# moonlight_application register map
Vendor: Nordic Semiconductor; Series: lumos; File version: 1
CPU: CM33 r0p4, little endian, MPU, FPU, 3 interrupt priority bits, 176 interrupts, 4 SAU regions
Registers are 32-bit, read-write, reset 0x0 unless marked. A register's access mark holds for its fields unless they carry their own. Offsets are from the block's base; [hi:lo] are bit positions; lines under a group give offsets from that group; {n}, {i} and the like mark numbered series; 'fields as' and 'values as' point back to an identical list.

## GLOBAL_RADIO_NS (part 2 of 4) — 2.4 GHz radio 0
Base 0x4008A000
Same registers: GLOBAL_RADIO_S 0x5008A000
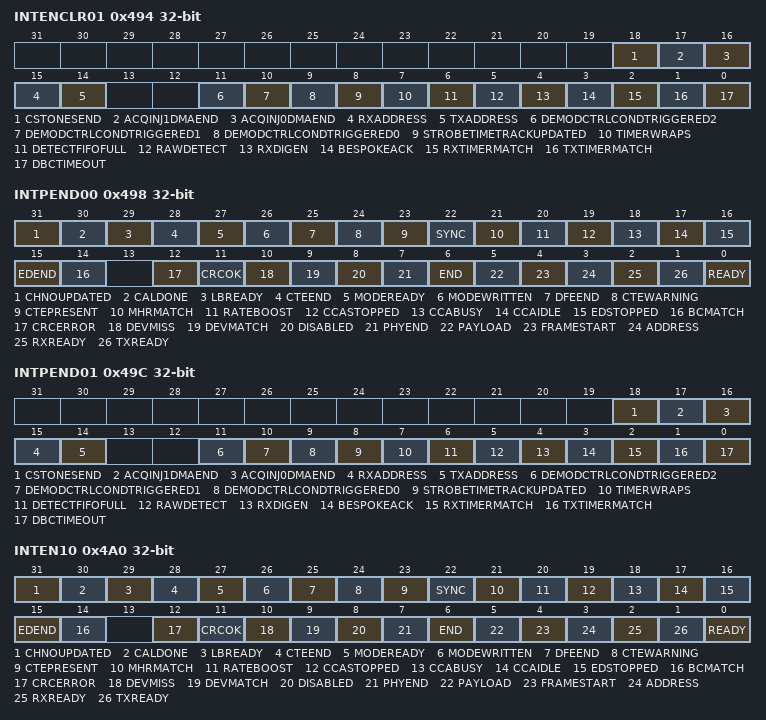
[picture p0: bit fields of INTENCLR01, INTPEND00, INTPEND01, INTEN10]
0x494 INTENCLR01 — Disable interrupt
  [all] fields
    on read: 0=Disabled (Read: Disabled); 1=Enabled (Read: Enabled) | on write: 1=Clear (Disable)
  [18] CSTONESEND — Write '1' to disable interrupt for event CSTONESEND
  [17] ACQINJ1DMAEND — Write '1' to disable interrupt for event ACQINJ1DMAEND
  [16] ACQINJ0DMAEND — Write '1' to disable interrupt for event ACQINJ0DMAEND
  [15] RXADDRESS — Write '1' to disable interrupt for event RXADDRESS
  [14] TXADDRESS — Write '1' to disable interrupt for event TXADDRESS
  [11] DEMODCTRLCONDTRIGGERED2 — Write '1' to disable interrupt for event DEMODCTRLCONDTRIGGERED2
  [10] DEMODCTRLCONDTRIGGERED1 — Write '1' to disable interrupt for event DEMODCTRLCONDTRIGGERED1
  [9] DEMODCTRLCONDTRIGGERED0 — Write '1' to disable interrupt for event DEMODCTRLCONDTRIGGERED0
  [8] STROBETIMETRACKUPDATED — Write '1' to disable interrupt for event STROBETIMETRACKUPDATED
  [7] TIMERWRAPS — Write '1' to disable interrupt for event TIMERWRAPS
  [6] DETECTFIFOFULL — Write '1' to disable interrupt for event DETECTFIFOFULL
  [5] RAWDETECT — Write '1' to disable interrupt for event RAWDETECT
  [4] RXDIGEN — Write '1' to disable interrupt for event RXDIGEN
  [3] BESPOKEACK — Write '1' to disable interrupt for event BESPOKEACK
  [2] RXTIMERMATCH — Write '1' to disable interrupt for event RXTIMERMATCH
  [1] TXTIMERMATCH — Write '1' to disable interrupt for event TXTIMERMATCH
  [0] DBCTIMEOUT — Write '1' to disable interrupt for event DBCTIMEOUT
0x498 INTPEND00 ro — Pending interrupts
  [all] fields
    on read: 0=NotPending (Read: Not pending); 1=Pending (Read: Pending)
  [31] CHNOUPDATED — Read pending status of interrupt for event CHNOUPDATED
  [30] CALDONE — Read pending status of interrupt for event CALDONE
  [29] LBREADY — Read pending status of interrupt for event LBREADY
  [28] CTEEND — Read pending status of interrupt for event CTEEND
  [27] MODEREADY — Read pending status of interrupt for event MODEREADY
  [26] MODEWRITTEN — Read pending status of interrupt for event MODEWRITTEN
  [25] DFEEND — Read pending status of interrupt for event DFEEND
  [24] CTEWARNING — Read pending status of interrupt for event CTEWARNING
  [23] CTEPRESENT — Read pending status of interrupt for event CTEPRESENT
  [22] SYNC — Read pending status of interrupt for event SYNC
  [21] MHRMATCH — Read pending status of interrupt for event MHRMATCH
  [20] RATEBOOST — Read pending status of interrupt for event RATEBOOST
  [19] CCASTOPPED — Read pending status of interrupt for event CCASTOPPED
  [18] CCABUSY — Read pending status of interrupt for event CCABUSY
  [17] CCAIDLE — Read pending status of interrupt for event CCAIDLE
  [16] EDSTOPPED — Read pending status of interrupt for event EDSTOPPED
  [15] EDEND — Read pending status of interrupt for event EDEND
  [14] BCMATCH — Read pending status of interrupt for event BCMATCH
  [12] CRCERROR — Read pending status of interrupt for event CRCERROR
  [11] CRCOK — Read pending status of interrupt for event CRCOK
  [10] DEVMISS — Read pending status of interrupt for event DEVMISS
  [9] DEVMATCH — Read pending status of interrupt for event DEVMATCH
  [8] DISABLED — Read pending status of interrupt for event DISABLED
  [7] PHYEND — Read pending status of interrupt for event PHYEND
  [6] END — Read pending status of interrupt for event END
  [5] PAYLOAD — Read pending status of interrupt for event PAYLOAD
  [4] FRAMESTART — Read pending status of interrupt for event FRAMESTART
  [3] ADDRESS — Read pending status of interrupt for event ADDRESS
  [2] RXREADY — Read pending status of interrupt for event RXREADY
  [1] TXREADY — Read pending status of interrupt for event TXREADY
  [0] READY — Read pending status of interrupt for event READY
0x49C INTPEND01 ro — Pending interrupts
  [all] fields
    values as the fields of INTPEND00
  [18] CSTONESEND — Read pending status of interrupt for event CSTONESEND
  [17] ACQINJ1DMAEND — Read pending status of interrupt for event ACQINJ1DMAEND
  [16] ACQINJ0DMAEND — Read pending status of interrupt for event ACQINJ0DMAEND
  [15] RXADDRESS — Read pending status of interrupt for event RXADDRESS
  [14] TXADDRESS — Read pending status of interrupt for event TXADDRESS
  [11] DEMODCTRLCONDTRIGGERED2 — Read pending status of interrupt for event DEMODCTRLCONDTRIGGERED2
  [10] DEMODCTRLCONDTRIGGERED1 — Read pending status of interrupt for event DEMODCTRLCONDTRIGGERED1
  [9] DEMODCTRLCONDTRIGGERED0 — Read pending status of interrupt for event DEMODCTRLCONDTRIGGERED0
  [8] STROBETIMETRACKUPDATED — Read pending status of interrupt for event STROBETIMETRACKUPDATED
  [7] TIMERWRAPS — Read pending status of interrupt for event TIMERWRAPS
  [6] DETECTFIFOFULL — Read pending status of interrupt for event DETECTFIFOFULL
  [5] RAWDETECT — Read pending status of interrupt for event RAWDETECT
  [4] RXDIGEN — Read pending status of interrupt for event RXDIGEN
  [3] BESPOKEACK — Read pending status of interrupt for event BESPOKEACK
  [2] RXTIMERMATCH — Read pending status of interrupt for event RXTIMERMATCH
  [1] TXTIMERMATCH — Read pending status of interrupt for event TXTIMERMATCH
  [0] DBCTIMEOUT — Read pending status of interrupt for event DBCTIMEOUT
0x4A0 INTEN10 — Enable or disable interrupt
  [all] fields
    0=Disabled; 1=Enabled
  [31] CHNOUPDATED — Enable or disable interrupt for event CHNOUPDATED
  [30] CALDONE — Enable or disable interrupt for event CALDONE
  [29] LBREADY — Enable or disable interrupt for event LBREADY
  [28] CTEEND — Enable or disable interrupt for event CTEEND
  [27] MODEREADY — Enable or disable interrupt for event MODEREADY
  [26] MODEWRITTEN — Enable or disable interrupt for event MODEWRITTEN
  [25] DFEEND — Enable or disable interrupt for event DFEEND
  [24] CTEWARNING — Enable or disable interrupt for event CTEWARNING
  [23] CTEPRESENT — Enable or disable interrupt for event CTEPRESENT
  [22] SYNC — Enable or disable interrupt for event SYNC
  [21] MHRMATCH — Enable or disable interrupt for event MHRMATCH
  [20] RATEBOOST — Enable or disable interrupt for event RATEBOOST
  [19] CCASTOPPED — Enable or disable interrupt for event CCASTOPPED
  [18] CCABUSY — Enable or disable interrupt for event CCABUSY
  [17] CCAIDLE — Enable or disable interrupt for event CCAIDLE
  [16] EDSTOPPED — Enable or disable interrupt for event EDSTOPPED
  [15] EDEND — Enable or disable interrupt for event EDEND
  [14] BCMATCH — Enable or disable interrupt for event BCMATCH
  [12] CRCERROR — Enable or disable interrupt for event CRCERROR
  [11] CRCOK — Enable or disable interrupt for event CRCOK
  [10] DEVMISS — Enable or disable interrupt for event DEVMISS
  [9] DEVMATCH — Enable or disable interrupt for event DEVMATCH
  [8] DISABLED — Enable or disable interrupt for event DISABLED
  [7] PHYEND — Enable or disable interrupt for event PHYEND
  [6] END — Enable or disable interrupt for event END
  [5] PAYLOAD — Enable or disable interrupt for event PAYLOAD
  [4] FRAMESTART — Enable or disable interrupt for event FRAMESTART
  [3] ADDRESS — Enable or disable interrupt for event ADDRESS
  [2] RXREADY — Enable or disable interrupt for event RXREADY
  [1] TXREADY — Enable or disable interrupt for event TXREADY
  [0] READY — Enable or disable interrupt for event READY
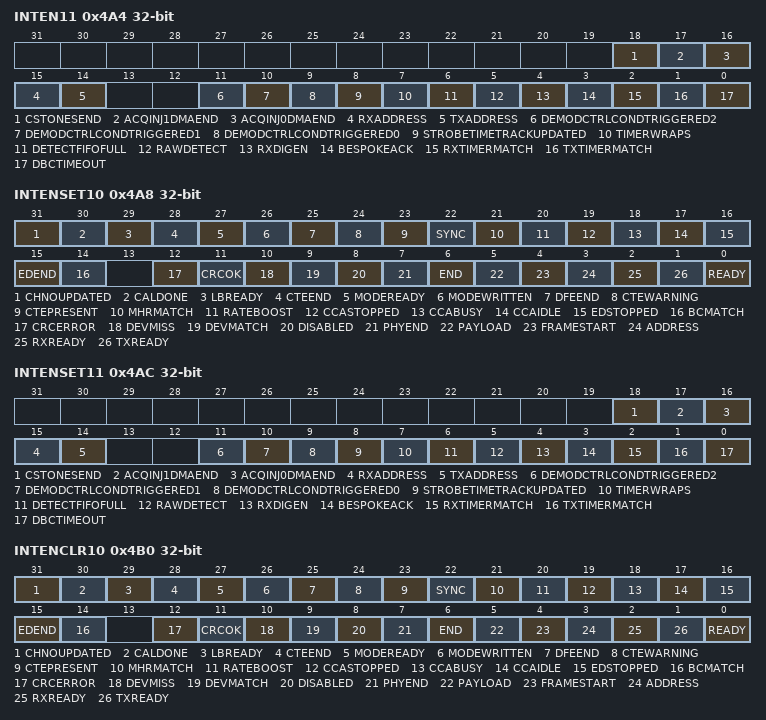
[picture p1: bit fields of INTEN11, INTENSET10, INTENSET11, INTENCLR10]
0x4A4 INTEN11 — Enable or disable interrupt
  [all] fields
    0=Disabled; 1=Enabled
  [18] CSTONESEND — Enable or disable interrupt for event CSTONESEND
  [17] ACQINJ1DMAEND — Enable or disable interrupt for event ACQINJ1DMAEND
  [16] ACQINJ0DMAEND — Enable or disable interrupt for event ACQINJ0DMAEND
  [15] RXADDRESS — Enable or disable interrupt for event RXADDRESS
  [14] TXADDRESS — Enable or disable interrupt for event TXADDRESS
  [11] DEMODCTRLCONDTRIGGERED2 — Enable or disable interrupt for event DEMODCTRLCONDTRIGGERED2
  [10] DEMODCTRLCONDTRIGGERED1 — Enable or disable interrupt for event DEMODCTRLCONDTRIGGERED1
  [9] DEMODCTRLCONDTRIGGERED0 — Enable or disable interrupt for event DEMODCTRLCONDTRIGGERED0
  [8] STROBETIMETRACKUPDATED — Enable or disable interrupt for event STROBETIMETRACKUPDATED
  [7] TIMERWRAPS — Enable or disable interrupt for event TIMERWRAPS
  [6] DETECTFIFOFULL — Enable or disable interrupt for event DETECTFIFOFULL
  [5] RAWDETECT — Enable or disable interrupt for event RAWDETECT
  [4] RXDIGEN — Enable or disable interrupt for event RXDIGEN
  [3] BESPOKEACK — Enable or disable interrupt for event BESPOKEACK
  [2] RXTIMERMATCH — Enable or disable interrupt for event RXTIMERMATCH
  [1] TXTIMERMATCH — Enable or disable interrupt for event TXTIMERMATCH
  [0] DBCTIMEOUT — Enable or disable interrupt for event DBCTIMEOUT
0x4A8 INTENSET10 — Enable interrupt
  [all] fields
    on read: 0=Disabled (Read: Disabled); 1=Enabled (Read: Enabled) | on write: 1=Set (Enable)
  [31] CHNOUPDATED — Write '1' to enable interrupt for event CHNOUPDATED
  [30] CALDONE — Write '1' to enable interrupt for event CALDONE
  [29] LBREADY — Write '1' to enable interrupt for event LBREADY
  [28] CTEEND — Write '1' to enable interrupt for event CTEEND
  [27] MODEREADY — Write '1' to enable interrupt for event MODEREADY
  [26] MODEWRITTEN — Write '1' to enable interrupt for event MODEWRITTEN
  [25] DFEEND — Write '1' to enable interrupt for event DFEEND
  [24] CTEWARNING — Write '1' to enable interrupt for event CTEWARNING
  [23] CTEPRESENT — Write '1' to enable interrupt for event CTEPRESENT
  [22] SYNC — Write '1' to enable interrupt for event SYNC
  [21] MHRMATCH — Write '1' to enable interrupt for event MHRMATCH
  [20] RATEBOOST — Write '1' to enable interrupt for event RATEBOOST
  [19] CCASTOPPED — Write '1' to enable interrupt for event CCASTOPPED
  [18] CCABUSY — Write '1' to enable interrupt for event CCABUSY
  [17] CCAIDLE — Write '1' to enable interrupt for event CCAIDLE
  [16] EDSTOPPED — Write '1' to enable interrupt for event EDSTOPPED
  [15] EDEND — Write '1' to enable interrupt for event EDEND
  [14] BCMATCH — Write '1' to enable interrupt for event BCMATCH
  [12] CRCERROR — Write '1' to enable interrupt for event CRCERROR
  [11] CRCOK — Write '1' to enable interrupt for event CRCOK
  [10] DEVMISS — Write '1' to enable interrupt for event DEVMISS
  [9] DEVMATCH — Write '1' to enable interrupt for event DEVMATCH
  [8] DISABLED — Write '1' to enable interrupt for event DISABLED
  [7] PHYEND — Write '1' to enable interrupt for event PHYEND
  [6] END — Write '1' to enable interrupt for event END
  [5] PAYLOAD — Write '1' to enable interrupt for event PAYLOAD
  [4] FRAMESTART — Write '1' to enable interrupt for event FRAMESTART
  [3] ADDRESS — Write '1' to enable interrupt for event ADDRESS
  [2] RXREADY — Write '1' to enable interrupt for event RXREADY
  [1] TXREADY — Write '1' to enable interrupt for event TXREADY
  [0] READY — Write '1' to enable interrupt for event READY
0x4AC INTENSET11 — Enable interrupt
  [all] fields
    values as the fields of INTENSET10
  [18] CSTONESEND — Write '1' to enable interrupt for event CSTONESEND
  [17] ACQINJ1DMAEND — Write '1' to enable interrupt for event ACQINJ1DMAEND
  [16] ACQINJ0DMAEND — Write '1' to enable interrupt for event ACQINJ0DMAEND
  [15] RXADDRESS — Write '1' to enable interrupt for event RXADDRESS
  [14] TXADDRESS — Write '1' to enable interrupt for event TXADDRESS
  [11] DEMODCTRLCONDTRIGGERED2 — Write '1' to enable interrupt for event DEMODCTRLCONDTRIGGERED2
  [10] DEMODCTRLCONDTRIGGERED1 — Write '1' to enable interrupt for event DEMODCTRLCONDTRIGGERED1
  [9] DEMODCTRLCONDTRIGGERED0 — Write '1' to enable interrupt for event DEMODCTRLCONDTRIGGERED0
  [8] STROBETIMETRACKUPDATED — Write '1' to enable interrupt for event STROBETIMETRACKUPDATED
  [7] TIMERWRAPS — Write '1' to enable interrupt for event TIMERWRAPS
  [6] DETECTFIFOFULL — Write '1' to enable interrupt for event DETECTFIFOFULL
  [5] RAWDETECT — Write '1' to enable interrupt for event RAWDETECT
  [4] RXDIGEN — Write '1' to enable interrupt for event RXDIGEN
  [3] BESPOKEACK — Write '1' to enable interrupt for event BESPOKEACK
  [2] RXTIMERMATCH — Write '1' to enable interrupt for event RXTIMERMATCH
  [1] TXTIMERMATCH — Write '1' to enable interrupt for event TXTIMERMATCH
  [0] DBCTIMEOUT — Write '1' to enable interrupt for event DBCTIMEOUT
0x4B0 INTENCLR10 — Disable interrupt
  [all] fields
    values as the fields of INTENCLR01
  [31] CHNOUPDATED — Write '1' to disable interrupt for event CHNOUPDATED
  [30] CALDONE — Write '1' to disable interrupt for event CALDONE
  [29] LBREADY — Write '1' to disable interrupt for event LBREADY
  [28] CTEEND — Write '1' to disable interrupt for event CTEEND
  [27] MODEREADY — Write '1' to disable interrupt for event MODEREADY
  [26] MODEWRITTEN — Write '1' to disable interrupt for event MODEWRITTEN
  [25] DFEEND — Write '1' to disable interrupt for event DFEEND
  [24] CTEWARNING — Write '1' to disable interrupt for event CTEWARNING
  [23] CTEPRESENT — Write '1' to disable interrupt for event CTEPRESENT
  [22] SYNC — Write '1' to disable interrupt for event SYNC
  [21] MHRMATCH — Write '1' to disable interrupt for event MHRMATCH
  [20] RATEBOOST — Write '1' to disable interrupt for event RATEBOOST
  [19] CCASTOPPED — Write '1' to disable interrupt for event CCASTOPPED
  [18] CCABUSY — Write '1' to disable interrupt for event CCABUSY
  [17] CCAIDLE — Write '1' to disable interrupt for event CCAIDLE
  [16] EDSTOPPED — Write '1' to disable interrupt for event EDSTOPPED
  [15] EDEND — Write '1' to disable interrupt for event EDEND
  [14] BCMATCH — Write '1' to disable interrupt for event BCMATCH
  [12] CRCERROR — Write '1' to disable interrupt for event CRCERROR
  [11] CRCOK — Write '1' to disable interrupt for event CRCOK
  [10] DEVMISS — Write '1' to disable interrupt for event DEVMISS
  [9] DEVMATCH — Write '1' to disable interrupt for event DEVMATCH
  [8] DISABLED — Write '1' to disable interrupt for event DISABLED
  [7] PHYEND — Write '1' to disable interrupt for event PHYEND
  [6] END — Write '1' to disable interrupt for event END
  [5] PAYLOAD — Write '1' to disable interrupt for event PAYLOAD
  [4] FRAMESTART — Write '1' to disable interrupt for event FRAMESTART
  [3] ADDRESS — Write '1' to disable interrupt for event ADDRESS
  [2] RXREADY — Write '1' to disable interrupt for event RXREADY
  [1] TXREADY — Write '1' to disable interrupt for event TXREADY
  [0] READY — Write '1' to disable interrupt for event READY
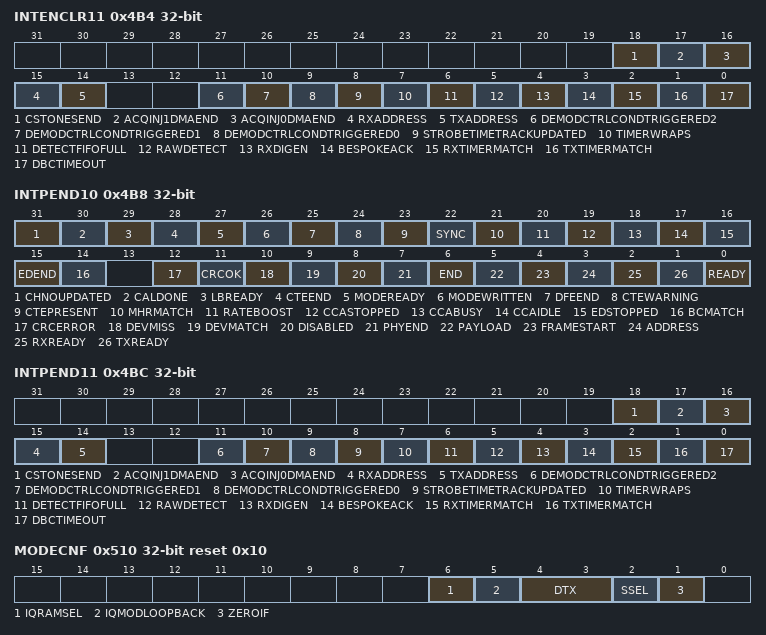
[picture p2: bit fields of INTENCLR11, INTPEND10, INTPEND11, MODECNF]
0x4B4 INTENCLR11 — Disable interrupt
  fields as INTENCLR01
0x4B8 INTPEND10 ro — Pending interrupts
  fields as INTPEND00
0x4BC INTPEND11 ro — Pending interrupts
  fields as INTPEND01
0x500 MODE — Data rate and modulation
  [3:0] MODE — Radio data rate and modulation setting. The radio supports frequency-shift keying (FSK) modulation.
    0=Nrf_1Mbit (1 Mbps Nordic proprietary radio mode); 1=Nrf_2Mbit (2 Mbps Nordic proprietary radio mode); 2=Nrf_250Kbit (Deprecated enumerator - 250 kbps Nordic proprietary radio mode); 3=Ble_1Mbit (1 Mbps BLE); 4=Ble_2Mbit (2 Mbps BLE); 5=Ble_LR125Kbit (Long range 125 kbps TX, 125 kbps and 500 kbps RX); 6=Ble_LR500Kbit (Long range 500 kbps TX, 125 kbps and 500 kbps RX); 9=Nrf_4Mbit0_5 (4 Mbps Nordic proprietary radio mode (BT=0.5/h=0.5)); 10=Nrf_4Mbit0_25 (4 Mbps Nordic proprietary radio mode (BT=0.5/h=0.25)); 15=Ieee802154_250Kbit (IEEE 802.15.4-2006 250 kbps)
0x504 MODEINTERNAL — Internal mode setting, active only when MODEPROGENABLE==1
  [3:0] MODEINTERNAL — Radio data rate and modulation setting. Same definition as MODE.
0x508 MODEPROGENABLE — Switch that enables programmable modes
  [0] MODEPROGENABLE — Enable manual triggering of MODEREADY event and activate MODEINTERNAL register (ie. MODEINTERNAL overrides MODE register)
0x510 MODECNF reset 0x10 — Radio mode configuration register
  [6] IQRAMSEL — IQ RAM select
    0=off (IQ RAM select off); 1=on (IQ RAM select on)
  [5] IQMODLOOPBACK — Loopback from IQ modulator
    0=Off (Digital loopback off); 1=On (Digital loopback on)
  [4:3] DTX — Default TX value. Specifies what the RADIO will transmit when it is not started, i.e. between: RADIO.EVENTS_READY and RADIO.TASKS_START RADIO.EVENTS_END and RADIO.TASKS_START RADIO.EVENTS_END and RADIO.EVENTS_DISABLED)
    0=B1 (Transmit '1'); 1=B0 (Transmit '0'); 2=Center (Transmit center frequency When tuning the crystal for centre frequency, the RADIO must be set in DTX = Center mode to be able to achieve the expected accuracy. This is only a valid setting for Nrf_1Mbit, Nrf_2Mbit, Nrf_250kbit, Ble_1Mbit and Ble_2Mbit.)
  [2] SSEL — Sideband select
    0=Low (Low-side LO); 1=High-side LO
  [1] ZEROIF — Zero-IF mode
    0=Default mode (heterodyne); 1=Zero-IF mode
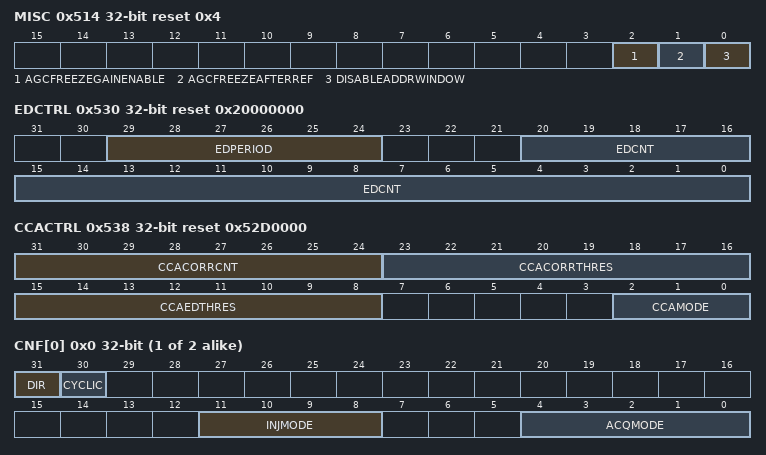
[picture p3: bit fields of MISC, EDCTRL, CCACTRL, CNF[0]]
0x514 MISC reset 0x4 — Misc configuration collection (to be renamed when more bits are defined)
  [2] AGCFREEZEGAINENABLE — Override AGC gain setting during CTE (from QOVERRIDE10)
    0=Adjust (AGC gain settings will keep adjusting during CTE); 1=Freeze (AGC gain settings will freeze (not keep adjusting) during CTE)
  [1] AGCFREEZEAFTERREF
    0=EntireCTE (Gain freeze will apply to whole CTE,); 1=AfterRefPeriod (Gain freeze will apply to only after reference period of CTE.)
  [0] DISABLEADDRWINDOW
    1=Disabled; 0=Enabled
0x520 STATE ro — Current radio state
  [3:0] STATE
    0=Disabled (RADIO is in the Disabled state); 1=RxRu (RADIO is in the RXRU state); 2=RxIdle (RADIO is in the RXIDLE state); 3=Rx (RADIO is in the RX state); 4=RxDisable (RADIO is in the RXDISABLED state); 9=TxRu (RADIO is in the TXRU state); 10=TxIdle (RADIO is in the TXIDLE state); 11=Tx (RADIO is in the TX state); 12=TxDisable (RADIO is in the TXDISABLED state)
0x530 EDCTRL reset 0x20000000 — IEEE 802.15.4 energy detect control
  [29:24] EDPERIOD — IEEE 802.15.4 energy detect/cca period, 4us resolution
  [20:0] EDCNT — IEEE 802.15.4 energy detect loop count
0x534 EDSAMPLE ro — IEEE 802.15.4 energy detect level
  [7:0] EDLVL
0x538 CCACTRL reset 0x52D0000 — IEEE 802.15.4 clear channel assessment control
  [31:24] CCACORRCNT — Limit for occurances above CCACORRTHRES. When not equal to zero the corrolator based signal detect is enabled.
  [23:16] CCACORRTHRES — CCA correlator busy threshold. Only relevant to CarrierMode, CarrierAndEdMode, and CarrierOrEdMode.
  [15:8] CCAEDTHRES — CCA energy busy threshold. Used in all the CCA modes except CarrierMode.
  [2:0] CCAMODE — CCA mode of operation
    0=EdMode (Energy above threshold); 1=CarrierMode (Carrier seen); 2=CarrierAndEdMode (Energy above threshold AND carrier seen); 3=CarrierOrEdMode (Energy above threshold OR carrier seen); 4=EdModeTest1 (Energy above threshold test mode that will abort when first ED measurement over threshold is seen. No averaging.)
0x540 DATAWHITEIV reset 0x40 — Data whitening initial value
  [5:0] DATAWHITEIV
0x548 ACQINJ group — Unspecified
  {0x0+4j} CNF[{j}] (j=0..1) — Description collection: Data acquisition/injection configuration
    [31] DIR — Data acquisition or injection
      0=Acq (Peripheral to memory); 1=Inj (Memory to peripheral)
    [30] CYCLIC — The END event of DMA automatically triggers the START event so that it continuously will store/read data
    [11:8] INJMODE — Injection mode (data from memory pushed to peripheral)
      0=OvrAdcIQ (Override ADC IQ); 6=OvrFeMixIQ (Override Frontend IQ after decimation and downmix); 8=OvrFeDecIQ (Override Frontend IQ after decimation); 10=AdPllMod (ADPLL custom modulation source)
    [4:0] ACQMODE — Acquisition mode (data from peripheral written to memory)
      0=AdcIQ; 2=AdcIQAndAgcGain (ADC IQ; AGC settings); 4=AgcGainAndPkd (AGC settings; peak detects; IF and baseband signal magnitudes); 6=FeIQ (Frontend IQ after decimation, downmix and filtering); 8=BbIQ (Baseband IQ after frequency offset compensation); 9=BbAaIQ (Baseband IQ after frequency offset compensation (both Hyper and AA demodulator)); 10=StdBits (Valid serial data from Standard Demodulator); 12=HypBits (Valid serial data from Hyper Demodulator); 13=AaBits (Valid serial data from AA Demodulator); 14=StdHypBitsMux (Serial data+valid muxed stream Hyper and Standard demodulators); 15=StdHypAaBitsMux (Serial data+valid muxed stream Hyper, Standard and AA demodulators); 16=FeDecIQ (Frontend IQ after decimation); 18=FeMixIQ (Frontend IQ after decimation and downmix); 20=AdPllTrace (ADPLL tracing)
{0x550+0x10*i} ACQINJDMA[{i}] (i=0..1) group — Unspecified
  0x00 ENABLE — Description cluster: Enable or disable data acquisition
    [0] ENABLE — Enable or disable data acquisition
      0=Disabled (Data acquisition is disabled); 1=Enabled (Data acquisition is enabled)
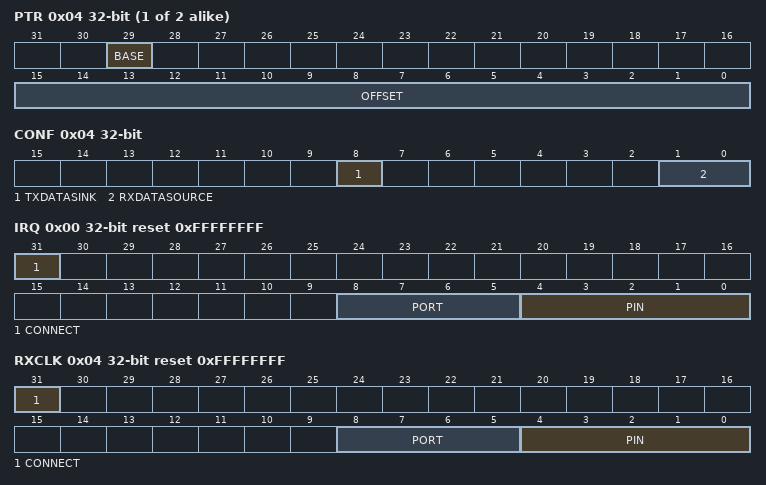
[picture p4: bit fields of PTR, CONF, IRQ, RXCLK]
  0x04 PTR — Description cluster: ACQ DMA pointer
    [29] BASE, [15:0] OFFSET
  0x08 MAXCNT reset 0x40 — Description cluster: Maximum number of 32-bit words to transfer
    [13:0] MAXCNT — Maximum number of 32-bit words to transfer
  0x0C AMOUNT ro — Description cluster: Number of 32-bit words transferred in the last transaction
    [13:0] AMOUNT — Number of 32-bit words transferred in the last transaction
0x570 TESTINTERFACE group — 2.4 GHz radio direct test interface
  0x00 LOCK rw-once — Security LOCK for test interface
    [0] LOCK — Write once to permanently lock or unlock.
      1=Lock (Interface is locked and cannot be enabled.); 0=Unlock (Interface is unlocked and can be enabled.)
  0x04 CONF — CONFIG for PSEL test interface
    [8] TXDATASINK — Sink select for Tx Data input. TX clock source is always SphynxSupport
      0=FelisTx (TX data sink is FelisTx); 1=SphynxSupport (TX data sink is SphynxSupport)
    [1:0] RXDATASOURCE — Source select for Rx data GPIO output and Rx clock output. Can optionally output Tx data that is transmitted and TX clock
      0=Standard (Data and clock source is from standard demodulator); 1=Hyper (Data and clock source is from hyper demodulator); 2=FelisTx (Data source is Tx data to SphynxSupport.); 3=MacTx (Data source is Tx data to FelisTx.)
  0x08 DEBUGPSEL group — Unspecified
    0x00 IRQ reset 0xFFFFFFFF — Pin select for RADIO irq
      [31] CONNECT — Connection
        1=Disconnected; 0=Connected
      [8:5] PORT — Port number
      [4:0] PIN — Pin number
    0x04 RXCLK reset 0xFFFFFFFF — Pin select for RXCLK
      fields as TESTINTERFACE.DEBUGPSEL.IRQ
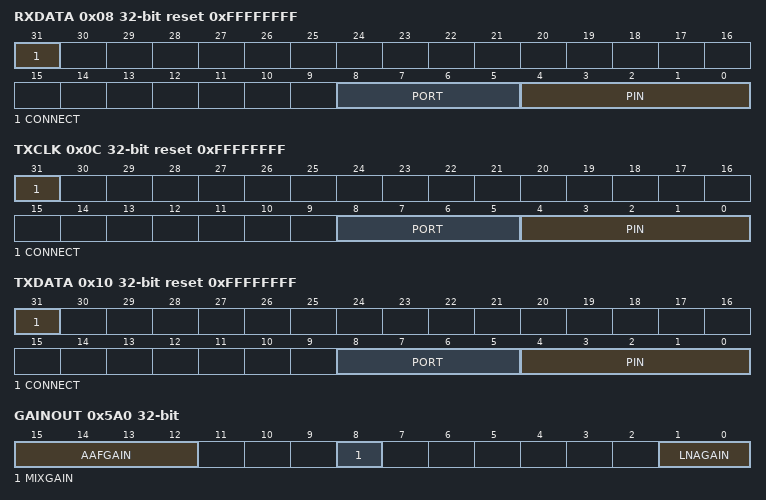
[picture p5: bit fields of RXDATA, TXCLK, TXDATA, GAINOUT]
    0x08 RXDATA reset 0xFFFFFFFF — Pin select for RXDATA
      fields as TESTINTERFACE.DEBUGPSEL.IRQ
    0x0C TXCLK reset 0xFFFFFFFF — Pin select for RADIO clock (direct mode, base band debug. txCk and ckDataIn signals)
      fields as TESTINTERFACE.DEBUGPSEL.IRQ
    0x10 TXDATA reset 0xFFFFFFFF — Pin select for RADIO data (direct mode, base band debug. txRadioData and dataIn signals)
      fields as TESTINTERFACE.DEBUGPSEL.IRQ
0x5A0 GAINOUT ro — Gain readout (LNA_OUT_SPI for nrf52/53)
  [15:12] AAFGAIN, [8] MIXGAIN, [1:0] LNAGAIN
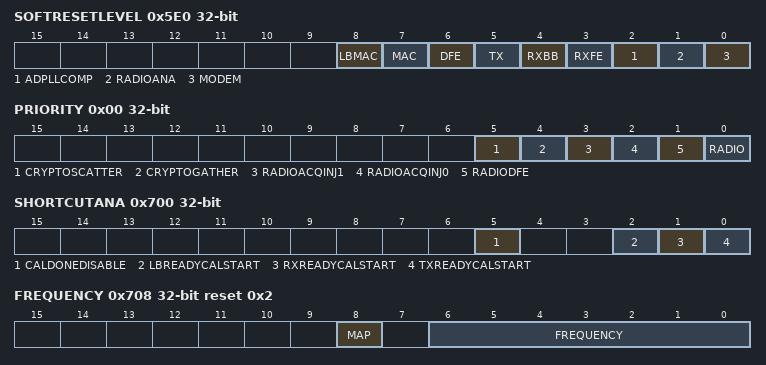
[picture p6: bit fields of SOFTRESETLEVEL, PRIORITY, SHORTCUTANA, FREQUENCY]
0x5E0 SOFTRESETLEVEL — Configure what level of reset is caused by TASKS_SOFTRESET in each of the submodules. At level 0, FSMs and public registers (including non-public fields) are reset. At level 1, also non-public registers are reset.
  [8] LBMAC, [7] MAC, [6] DFE, [5] TX, [4] RXBB, [3] RXFE, [2] ADPLLCOMP, [1] RADIOANA, [0] MODEM
0x5F0 AHBMASTERS group — For setting priorities among RADIO/CRYPTO AHB masters if interfaced with Nordic's AMBA Interconnect IP
  0x00 PRIORITY — Unspecified
    [all] fields
      0=LOW (Lowest Priority Level); 1=HIGH (Highest Priority Level)
    [5] CRYPTOSCATTER — Priority level for AHB master CRYPTOSCATTER
    [4] CRYPTOGATHER — Priority level for AHB master CRYPTOGATHER
    [3] RADIOACQINJ1 — Priority level for AHB master RADIOACQINJ1
    [2] RADIOACQINJ0 — Priority level for AHB master RADIOACQINJ0
    [1] RADIODFE — Priority level for AHB master RADIODFE
    [0] RADIO — Priority level for AHB master RADIO
0x700 SHORTCUTANA — Internal shortcuts for RADIO PHY
  [5] CALDONEDISABLE — Internal shortcut
  [2] LBREADYCALSTART — Internal shortcut
  [1] RXREADYCALSTART — Internal shortcut
  [0] TXREADYCALSTART — Internal shortcut
0x704 TIMING
  [0] RU — 0: Default ramp-up time, compatible with 180nm radio. 1: Fast ramp-up.
0x708 FREQUENCY reset 0x2
  [8] MAP — Channel map selection. 0: Channel map between 2400 MHZ to 2500 MHz, Frequency = 2400 + FREQUENCY (MHz). 1: Channel map between 2360 MHZ to 2460 MHz, Frequency = 2360 + FREQUENCY (MHz).
  [6:0] FREQUENCY — Radio channel frequency. Frequency = 2400 + FREQUENCY (MHz).
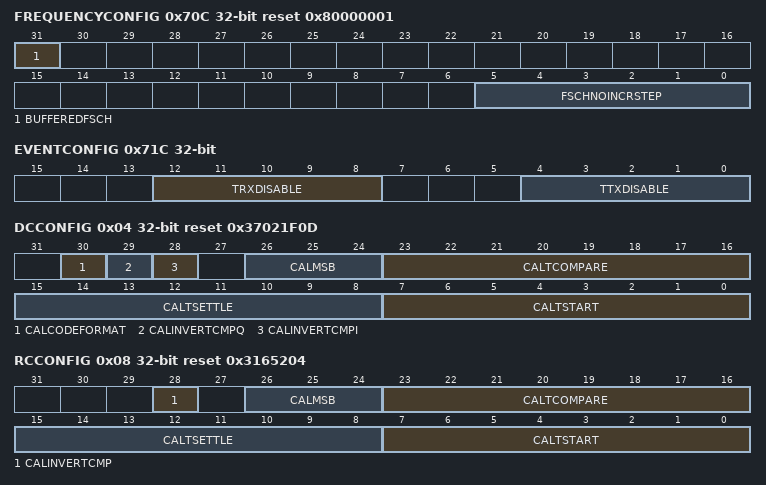
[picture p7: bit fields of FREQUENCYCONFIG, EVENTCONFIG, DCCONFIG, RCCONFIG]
0x70C FREQUENCYCONFIG reset 0x80000001 — Configuration of frequency control
  [31] BUFFEREDFSCH — Set to high to buffer FREQUENCY register so that sub-modules in the MMI will only update next frequency config at TX_EN, RX_EN and LB_EN. Set to low if special test is needed for FS test.
  [5:0] FSCHNOINCRSTEP — Radio channel incremental step unit
0x710 TXPOWER reset 0x13 — Output power
  [8:0] TXPOWER — RADIO output power
    63=Pos10dBm (+10 dBm); 57=Pos9dBm (+9 dBm); 51=Pos8dBm (+8 dBm); 45=Pos7dBm (+7 dBm); 40=Pos6dBm (+6 dBm); 35=Pos5dBm (+5 dBm); 31=Pos4dBm (+4 dBm); 27=Pos3dBm (+3 dBm); 24=Pos2dBm (+2 dBm); 21=Pos1dBm (+1 dBm); 19=0dBm; 17=Neg1dBm (-1 dBm); 15=Neg2dBm (-2 dBm); 13=Neg3dBm (-3 dBm); 11=Neg4dBm (-4 dBm); 10=Neg5dBm (-5 dBm); 9=Neg6dBm (-6 dBm); 8=Neg7dBm (-7 dBm); 7=Neg8dBm (-8 dBm); 6=Neg9dBm (-9 dBm); 5=Neg10dBm (-10 dBm); 4=Neg12dBm (-12 dBm); 3=Neg14dBm (-14 dBm); 2=Neg16dBm (-16 dBm); 1=Neg20dBm (-20 dBm); 0=Neg26dBm (-26 dBm); 0x130=Neg40dBm (-40 dBm); 0x110=Neg46dBm (-46 dBm)
0x714 TIFS — Interframe spacing in us
  [9:0] TIFS — Interframe spacing in us. Interframe space is the time interval between two consecutive packets. It is defined as the time, in microseconds, from the end of the last bit of the previous packet to the start of the first bit of the subsequent packet.
0x718 RSSISAMPLE ro reset 0x7F
  [6:0] RSSISAMPLE — RSSI sample result. The value of this register is read as a positive value while the actual received signal strength is a negative value. Actual received signal strength is therefore as follows: received signal strength = -A dBm.
0x71C EVENTCONFIG — Event configuration
  [12:8] TRXDISABLE — Transition time from RXDISABLE state to DISABLED state Configurable time, in us, between RADIO.EVENTS_END and RADIO.EVENTS_DISABLED when using the shortcut between RADIO.EVENTS_END and RADIO.TASKS_DISABLE. The minimum time between RADIO.TASKS_DISABLE and RADIO.EVENTS_DISABLED is described in electrical parameters. The minimum time will be used if the configured time is set shorter than the minimum time. Depending on configuration setting the DISABLED event may experience some jitter, see electrical parameters for more information. (unit: 1us)
  [4:0] TTXDISABLE — Transition time from TXDISABLE state to DISABLED state Configurable time, in us, between RADIO.EVENTS_END and RADIO.EVENTS_DISABLED when using the shortcut between RADIO.EVENTS_END and RADIO.TASKS_DISABLE. The minimum time between RADIO.TASKS_DISABLE and RADIO.EVENTS_DISABLED is described in the electrical parameters. The minimum time will be used if the configured time is set shorter than the minimum time. Depending on configuration setting the DISABLED event may experience some jitter, see electrical parameters for more information. Note: The RADIO shall be disabled as normal when DISABLE task is triggered, it is only the DISABLED event that can be delayed. Note: The TIFS mechanism shall not be affected by the value specified in this field. (unit: 1us)
0x720 CALIBRATION group — Unspecified
  0x00 TARGET — Select target for calibration
    [0] CALTARGET — Calibration target selection for calibration engine, 0: DC_CAL, 1: RC_CAL
  0x04 DCCONFIG reset 0x37021F0D — Calibration config when CALTARGET=DC_CAL
    [30] CALCODEFORMAT — 0: 2's complement, 1: sign-magnitude
    [29] CALINVERTCMPQ — 1: invert calCmp2 (Q) before it goes into calibration engine #2
    [28] CALINVERTCMPI — 1: invert calCmp1 (I) before it goes into calibration engine #1
    [26:24] CALMSB — Index of most significant bit to be calibrated (add 1 to get number of bits)
    [23:16] CALTCOMPARE — Compare wait time (default 93.75ns)
    [15:8] CALTSETTLE — Settle wait time (default 1000ns)
    [7:0] CALTSTART — Startup wait time (default 437.5ns)
  0x08 RCCONFIG reset 0x3165204 — Calibration config when CALTARGET=RC_CAL
    [28] CALINVERTCMP — 1: invert calCmp1 before it goes into calibration engine #1
    [26:24] CALMSB — Index of most significant bit to be calibrated (add 1 to get number of bits)
    [23:16] CALTCOMPARE — Compare wait time (default 718.75ns)
    [15:8] CALTSETTLE — Settle wait time (default 2593.75ns)
    [7:0] CALTSTART — Startup wait time (default 156.25ns)
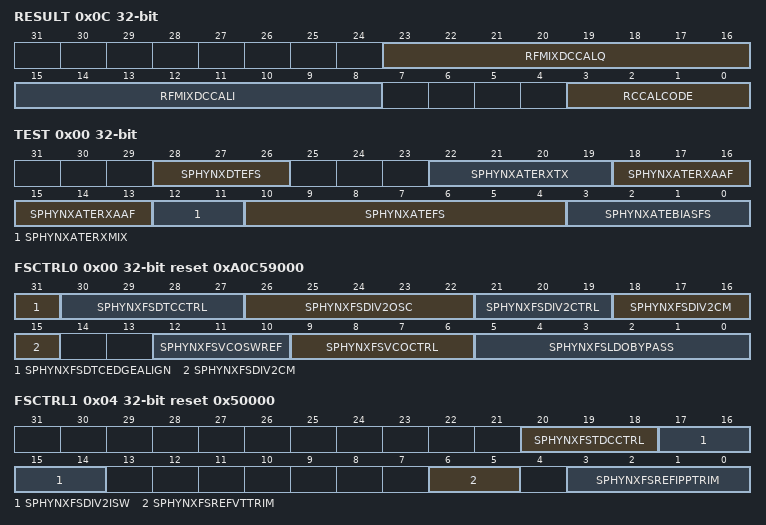
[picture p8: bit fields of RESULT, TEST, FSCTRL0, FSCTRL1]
  0x0C RESULT ro — Calibration result
    [23:16] RFMIXDCCALQ — Calibration result from DC offset calibration on channel Q
    [15:8] RFMIXDCCALI — Calibration result from DC offset calibration on channel I
    [3:0] RCCALCODE — Calibration result from RC calibration
0x730 SPHYNXANATEST group — Unspecified
  0x00 TEST — Control of analog and digital test bus output from Sphynx
    [28:26] SPHYNXDTEFS — Digital test enable for digital logic in analog macro
    [22:19] SPHYNXATERXTX — Analog test enable for RX TX
    [18:13] SPHYNXATERXAAF — Analog test enable for RX AAF
    [12:11] SPHYNXATERXMIX — Analog test enable for RX MIX
    [10:4] SPHYNXATEFS — Analog test enable for FS
    [3:0] SPHYNXATEBIASFS — Analog test enable for BIAS_FS
0x734 SPHYNXANA group — Unspecified
  0x00 FSCTRL0 reset 0xA0C59000 — Control to frequency synthesizer of Sphynx
    [31] SPHYNXFSDTCEDGEALIGN — Resync at flip flop inside DTC
    [30:27] SPHYNXFSDTCCTRL — DTC control
    [26:22] SPHYNXFSDIV2OSC — Spare, not used
    [21:19] SPHYNXFSDIV2CTRL — Spare, not used
    [18:15] SPHYNXFSDIV2CM — Spare, not used
    [12:10] SPHYNXFSVCOSWREF — FS swing calibration
    [9:6] SPHYNXFSVCOCTRL — Spare, not used
    [5:0] SPHYNXFSLDOBYPASS — Bypass FS LDOs
  0x04 FSCTRL1 reset 0x50000 — Control to frequency synthesizer of Sphynx
    [20:18] SPHYNXFSTDCCTRL — Spare, not used
    [17:14] SPHYNXFSDIV2ISW — [2:0] Adjust voltage for back bias of injection switch; [3] Spare
    [6:5] SPHYNXFSREFVTTRIM — For voltage tuning of reference
    [3:0] SPHYNXFSREFIPPTRIM — For current calibration
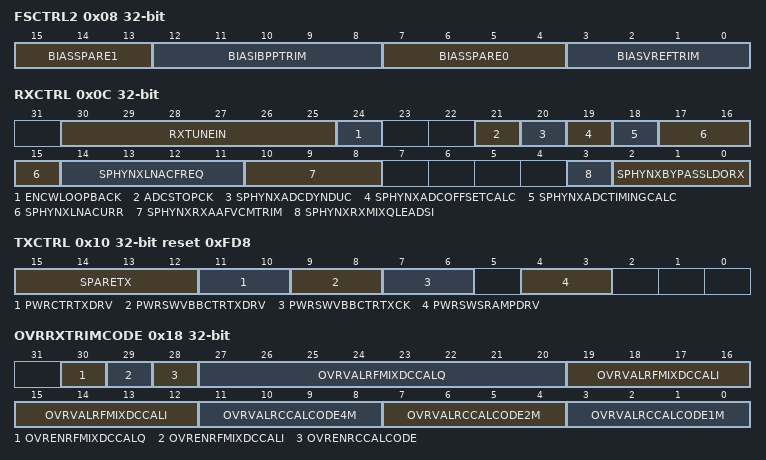
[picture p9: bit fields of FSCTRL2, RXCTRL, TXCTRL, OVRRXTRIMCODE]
  0x08 FSCTRL2 — Control to frequency synthesizer of Sphynx
    [15:13] BIASSPARE1 — BIAS_RXTX_CFG[15:13]
    [12:8] BIASIBPPTRIM — BIAS_RXTX_CFG[12:8]
    [7:4] BIASSPARE0 — BIAS_RXTX_CFG[7:4]
    [3:0] BIASVREFTRIM — BIAS_RXTX_CFG[3:0]
  0x0C RXCTRL — Control to receiver of Sphynx
    [30:25] RXTUNEIN — Controls TX_PWR_0V8/PWRCTR_TX_0V9 when in RX or Loopback
    [24] ENCWLOOPBACK — Enable CW loopback
    [21] ADCSTOPCK — ADC_CFG_0V8[3]
    [20] SPHYNXADCDYNDUC — ADC_CFG_0V8[2]: Dynamic duty cycle of sampling clock
    [19] SPHYNXADCOFFSETCALC — ADC_CFG_0V8[1]: Enabling of offset calculation
    [18] SPHYNXADCTIMINGCALC — ADC_CFG_0V8[0]: Calculation of ADC timing margin
    [17:15] SPHYNXLNACURR — LNA current setting
    [14:11] SPHYNXLNACFREQ — LNA center frequency settings
    [10:8] SPHYNXRXAAFVCMTRIM — VCM trim values for RX_AAF
    [3] SPHYNXRXMIXQLEADSI — 1: output from MIX_AMP is Q leading I, 0 output from MIX_AMP is I leading Q
    [2:0] SPHYNXBYPASSLDORX — Bypass Rx LDOs
  0x10 TXCTRL reset 0xFD8 — Control to transmitter of Sphynx
    [15:12] SPARETX — SPARE_TX_0V9
    [11:10] PWRCTRTXDRV — PWRCTR_TX_DRV_0V9
    [9:8] PWRSWVBBCTRTXDRV — PWRSW_VBBCTR_TXDRV_0V9
    [7:6] PWRSWVBBCTRTXCK — PWRSW_VBBCTR_TXCK_0V9
    [4:3] PWRSWSRAMPDRV — PWRSW_SRAMP_DRV_0V9
  0x14 MODEDEPENDENT — Mode dependent register of Sphynx
    [1:0] SPHYNXRXAAFFREQ — Select Cut-Off Frequency for the AAF
      0=2 MHz (for 1 MHz IF frequency); 1=4 MHz (for 2 MHz IF frequency); 2=6 MHz (for 4 MHz IF frequency)
  0x18 OVRRXTRIMCODE — Override trim codes to the receiver of Sphynx
    [30] OVRENRFMIXDCCALQ — For RXMIX_DCCAL_Q_0V8, 0: controlled by CalibrationEngine, 1: overridden by register
    [29] OVRENRFMIXDCCALI — For RXMIX_DCCAL_I_0V8, 0: controlled by CalibrationEngine, 1: overridden by register
    [28] OVRENRCCALCODE — For RCCAL_CODE_0V8, 0: controlled by CalibrationEngine, 1: overridden by register
    [27:20] OVRVALRFMIXDCCALQ — Override values on RXMIX_DCCAL_Q_0V8
    [19:12] OVRVALRFMIXDCCALI — Override values on RXMIX_DCCAL_I_0V8
    [11:8] OVRVALRCCALCODE4M — Override values on RCCAL_CODE and RX_AAF_RCTRIMM (when IF is 4M)
    [7:4] OVRVALRCCALCODE2M — Override values on RCCAL_CODE and RX_AAF_RCTRIMM (when IF is 2M)
    [3:0] OVRVALRCCALCODE1M — Override values on RCCAL_CODE and RX_AAF_RCTRIMM (when IF is 1M)
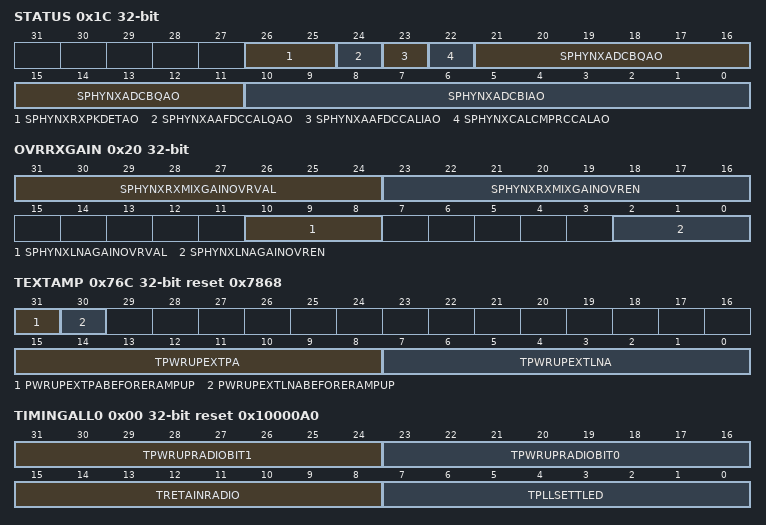
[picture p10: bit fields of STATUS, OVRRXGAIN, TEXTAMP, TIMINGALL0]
  0x1C STATUS ro — Readout raw status of signals output from Sphynx
    [26:25] SPHYNXRXPKDETAO — Raw peak detector output from RX_PKDET
    [24] SPHYNXAAFDCCALQAO — Raw comparator output of DC calibration from RX_AAF Q channel
    [23] SPHYNXAAFDCCALIAO — Raw comparator output of DC calibration from RX_AAF I channel
    [22] SPHYNXCALCMPRCCALAO — Raw comparator output of RC calibration from RC_CAL
    [21:11] SPHYNXADCBQAO — Raw ADC Q channel output from RX_SAR2
    [10:0] SPHYNXADCBIAO — Raw ADC I channel output from RX_SAR2
  0x20 OVRRXGAIN — Analog rx gain override
    [31:24] SPHYNXRXMIXGAINOVRVAL — Override value for RXMIX_GAIN_0V8, each bit can be overriden individually
    [23:16] SPHYNXRXMIXGAINOVREN — Override enable for RXMIX_GAIN_0V8, each bit can be overriden individually
    [10:8] SPHYNXLNAGAINOVRVAL — Override value for LNA_GAIN_0V8, each bit can be overriden individually
    [2:0] SPHYNXLNAGAINOVREN — Override enable for LNA_GAIN_0V8, each bit can be overriden individually
  0x24 CLOCKSOURCE — Choose between two clock sources
    [0] ENCK64MBUFSIN — Enable clock buffer from 64MHz input
      0=32MHz (Use clock from 32MHz XOSC (Lilium)); 1=64MHz (Use clock from 64MHz XOSC (Halti))
0x76C TEXTAMP reset 0x7868 — Timing control of external RADIO amplifier (LNA/PA)
  [31] PWRUPEXTPABEFORERAMPUP — In legacy timing mode, pwrupExtPa can be powered on before starting to ramp up by setting this registers to 1
    0=AfterRampup (Power up external PA at (RADIO_rampup_start_time + TPWRUPEXTPA)); 1=BeforeRampup (Power up external PA at (RADIO_rampup_start_time - TPWRUPEXTPA))
  [30] PWRUPEXTLNABEFORERAMPUP — In legacy timing mode, pwrupExtLna can be powered on before starting to ramp up by setting this registers to 1
    0=AfterRampup (Power up external LNA at (RADIO_rampup_start_time + TPWRUPEXTLNA)); 1=BeforeRampup (Power up external LNA at (RADIO_rampup_start_time - TPWRUPEXTLNA))
  [15:8] TPWRUPEXTPA — Timing control of PwrupExtPa (unit: 0.25us)
  [7:0] TPWRUPEXTLNA — Timing control of PwrupExtLna (unit: 0.25us)
0x770 TIMINGENGINE group — Unspecified
  0x00 TIMINGALL0 reset 0x10000A0 — Timing parameters for signals activated in both Rx and Tx mode
    [31:24] TPWRUPRADIOBIT1 — Timing control of pwrupRadio[1] (unit: 0.25us)
    [23:16] TPWRUPRADIOBIT0 — Timing control of pwrupRadio[0] (unit: 0.25us)
    [15:8] TRETAINRADIO — Timing control of retainRadio (unit: 0.25us)
    [7:0] TPLLSETTLED — Timing control of pllSettled (unit: 0.25us)
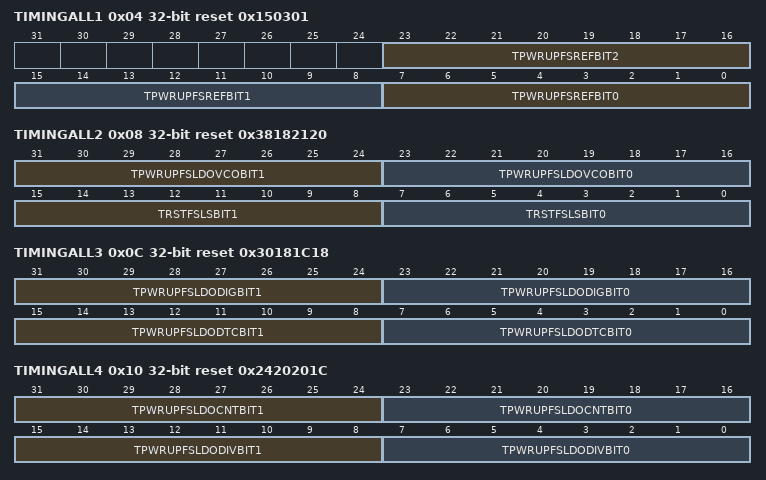
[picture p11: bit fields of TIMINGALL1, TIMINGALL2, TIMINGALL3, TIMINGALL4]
  0x04 TIMINGALL1 reset 0x150301 — Timing parameters for signals activated in both Rx and Tx mode
    [23:16] TPWRUPFSREFBIT2 — Timing control of PwrupFsRef[2] (unit: 0.25us)
    [15:8] TPWRUPFSREFBIT1 — Timing control of PwrupFsRef[1] (unit: 0.25us)
    [7:0] TPWRUPFSREFBIT0 — Timing control of PwrupFsRef[0] (unit: 0.25us)
  0x08 TIMINGALL2 reset 0x38182120 — Timing parameters for signals activated in both Rx and Tx mode
    [31:24] TPWRUPFSLDOVCOBIT1 — Timing control of PwrupFsLdoVco[1] (unit: 0.25us)
    [23:16] TPWRUPFSLDOVCOBIT0 — Timing control of PwrupFsLdoVco[0] (unit: 0.25us)
    [15:8] TRSTFSLSBIT1 — Timing control of RstFsLs[1] (unit: 0.25us)
    [7:0] TRSTFSLSBIT0 — Timing control of RstFsLs[0] (unit: 0.25us)
  0x0C TIMINGALL3 reset 0x30181C18 — Timing parameters for signals activated in both Rx and Tx mode
    [31:24] TPWRUPFSLDODIGBIT1 — Timing control of PwrupFsLdoDig[1] (unit: 0.25us)
    [23:16] TPWRUPFSLDODIGBIT0 — Timing control of PwrupFsLdoDig[0] (unit: 0.25us)
    [15:8] TPWRUPFSLDODTCBIT1 — Timing control of PwrupFsLdoDtc[1] (unit: 0.25us)
    [7:0] TPWRUPFSLDODTCBIT0 — Timing control of PwrupFsLdoDtc[0] (unit: 0.25us)
  0x10 TIMINGALL4 reset 0x2420201C — Timing parameters for signals activated in both Rx and Tx mode
    [31:24] TPWRUPFSLDOCNTBIT1 — Timing control of PwrupFsLdoCnt[1] (unit: 0.25us)
    [23:16] TPWRUPFSLDOCNTBIT0 — Timing control of PwrupFsLdoCnt[0] (unit: 0.25us)
    [15:8] TPWRUPFSLDODIVBIT1 — Timing control of PwrupFsLdoDiv[1] (unit: 0.25us)
    [7:0] TPWRUPFSLDODIVBIT0 — Timing control of PwrupFsLdoDiv[0] (unit: 0.25us)
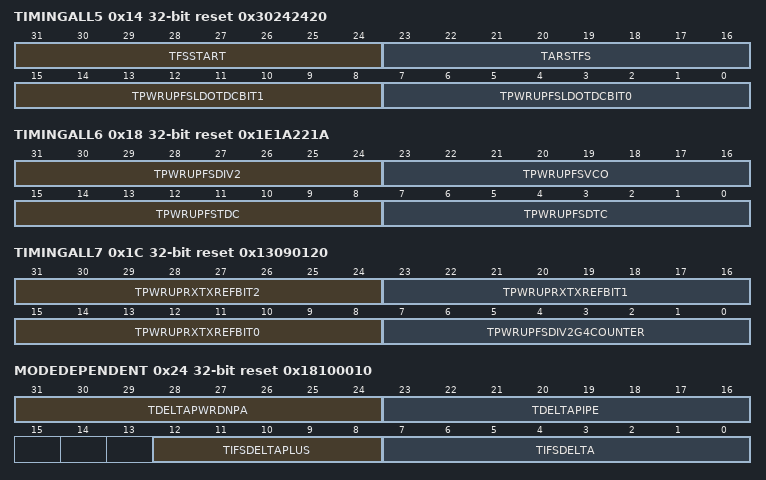
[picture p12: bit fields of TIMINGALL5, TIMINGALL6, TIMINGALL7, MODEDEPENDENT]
  0x14 TIMINGALL5 reset 0x30242420 — Timing parameters for signals activated in both Rx and Tx mode
    [31:24] TFSSTART — Timing control of FsStart (unit: 0.25us)
    [23:16] TARSTFS — Timing control of ArstFs (unit: 0.25us)
    [15:8] TPWRUPFSLDOTDCBIT1 — Timing control of PwrupFsLdoTdc[1] (unit: 0.25us)
    [7:0] TPWRUPFSLDOTDCBIT0 — Timing control of PwrupFsLdoTdc[0] (unit: 0.25us)
  0x18 TIMINGALL6 reset 0x1E1A221A — Timing parameters for signals activated in both Rx and Tx mode
    [31:24] TPWRUPFSDIV2 — Timing control of PwrupFsDiv2 (unit: 0.25us)
    [23:16] TPWRUPFSVCO — Timing control of PwrupFsVco (unit: 0.25us)
    [15:8] TPWRUPFSTDC — Timing control of PwrupFsTdc (unit: 0.25us)
    [7:0] TPWRUPFSDTC — Timing control of PwrupFsDtc (unit: 0.25us)
  0x1C TIMINGALL7 reset 0x13090120 — Timing parameters for signals activated in both Rx and Tx mode
    [31:24] TPWRUPRXTXREFBIT2 — Timing control of PwrupRxTxRef[2] (unit: 0.25us)
    [23:16] TPWRUPRXTXREFBIT1 — Timing control of PwrupRxTxRef[1] (unit: 0.25us)
    [15:8] TPWRUPRXTXREFBIT0 — Timing control of PwrupRxTxRef[0] (unit: 0.25us)
    [7:0] TPWRUPFSDIV2G4COUNTER — Timing control of PwrupFsDiv2g4Counter (unit: 0.25us)
  0x20 TIMINGALL8 reset 0x28 — Timing parameters for signals activated in both Rx and Tx mode
    [7:0] TRSTFSLSBIT2 — Timing control of RstFsLs[2] (unit: 0.25us)
  0x24 MODEDEPENDENT reset 0x18100010 — Mode dependent timing parameters
    [31:24] TDELTAPWRDNPA — Timing control of DeltaPwrdnPa (unit: 0.25us)
    [23:16] TDELTAPIPE — Timing control of DeltaPipe (unit: 0.25us)
    [12:8] TIFSDELTAPLUS — Timing control of IfsDeltaPlus (unit: 0.25us)
    [7:0] TIFSDELTA — Timing control of IfsDelta (unit: 0.25us)
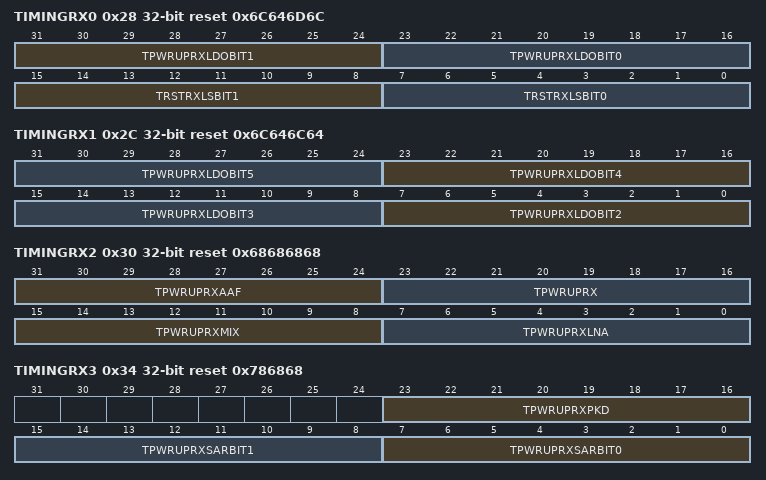
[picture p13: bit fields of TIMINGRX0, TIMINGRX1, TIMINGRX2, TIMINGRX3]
  0x28 TIMINGRX0 reset 0x6C646D6C — Timing parameters for signals activated in Rx mode
    [31:24] TPWRUPRXLDOBIT1 — Timing control of PwrupRxLdo[1] (unit: 0.25us)
    [23:16] TPWRUPRXLDOBIT0 — Timing control of PwrupRxLdo[0] (unit: 0.25us)
    [15:8] TRSTRXLSBIT1 — Timing control of RstRxLs[1] (unit: 0.25us)
    [7:0] TRSTRXLSBIT0 — Timing control of RstRxLs[0] (unit: 0.25us)
  0x2C TIMINGRX1 reset 0x6C646C64 — Timing parameters for signals activated in Rx mode
    [8n-9:8n-16] TPWRUPRXLDOBIT{n} (n=2..5) — Timing control of PwrupRxLdo[{n}] (unit: 0.25us)
  0x30 TIMINGRX2 reset 0x68686868 — Timing parameters for signals activated in Rx mode
    [31:24] TPWRUPRXAAF — Timing control of PwrupRxAaf (unit: 0.25us)
    [23:16] TPWRUPRX — Timing control of PwrupRx (unit: 0.25us)
    [15:8] TPWRUPRXMIX — Timing control of PwrupRxMix (unit: 0.25us)
    [7:0] TPWRUPRXLNA — Timing control of PwrupRxLna (unit: 0.25us)
  0x34 TIMINGRX3 reset 0x786868 — Timing parameters for signals activated in Rx mode
    [23:16] TPWRUPRXPKD — Spare register. Power up peak detector is now tied with power up mixer.
    [15:8] TPWRUPRXSARBIT1 — Timing control of PwrupRxSar[1] (unit: 0.25us)
    [7:0] TPWRUPRXSARBIT0 — Timing control of PwrupRxSar[0] (unit: 0.25us)
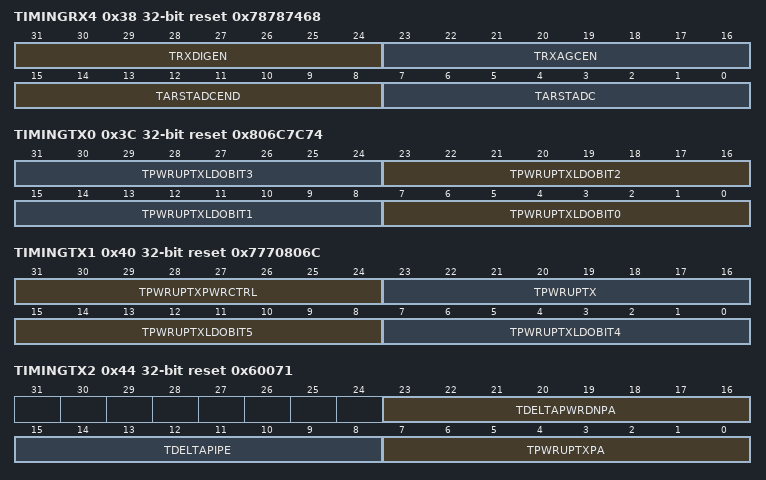
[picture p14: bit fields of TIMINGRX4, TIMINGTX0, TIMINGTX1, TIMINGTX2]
  0x38 TIMINGRX4 reset 0x78787468 — Timing parameters for signals activated in Rx mode
    [31:24] TRXDIGEN — Timing control of RxDigEn (unit: 0.25us)
    [23:16] TRXAGCEN — Timing control of RxAgcEn (unit: 0.25us)
    [15:8] TARSTADCEND — Timing control of ArstAdcEnd (unit: 0.25us)
    [7:0] TARSTADC — Timing control of ArstAdc (unit: 0.25us)
  0x3C TIMINGTX0 reset 0x806C7C74 — Timing parameters for signals activated in Tx mode
    [8n+7:8n] TPWRUPTXLDOBIT{n} (n=0..3) — Timing control of PwrupTxLdo[{n}] (unit: 0.25us)
  0x40 TIMINGTX1 reset 0x7770806C — Timing parameters for signals activated in Tx mode
    [31:24] TPWRUPTXPWRCTRL — Timing control of PwrupTxPwrCtrl (unit: 0.25us)
    [23:16] TPWRUPTX — Timing control of PwrupTx (unit: 0.25us)
    [15:8] TPWRUPTXLDOBIT5 — Timing control of PwrupTxLdo[5] (unit: 0.25us)
    [7:0] TPWRUPTXLDOBIT4 — Timing control of PwrupTxLdo[4] (unit: 0.25us)
  0x44 TIMINGTX2 reset 0x60071 — Timing parameters for signals activated in Tx mode
    [23:16] TDELTAPWRDNPA — Timing control of DeltaPwrdnPa (unit: 0.25us)
    [15:8] TDELTAPIPE — Timing control of DeltaPipe (unit: 0.25us)
    [7:0] TPWRUPTXPA — Timing control of PwrupTxPa (unit: 0.25us)
  0x48 CONFIG reset 0x6020464 — Configuration of timing control
    [31:24] TREDUCETRXSWITCHEXTRA — Extra reduced timing for on-the-fly Tx->Rx (select signals) (unit: 0.25us)
    [17:8] TRXTXTURNAROUNDHOLD — Additional delay to hold Tx/Rx turnaround (unit: 0.25us)
    [7:0] TREDUCETRXSWITCH — Reduced timing for on-the-fly switch on both Rx->Tx and Tx->Rx (unit: 0.25us)
  0x4C OVRENALL — Enable or disable override of signals
    [30:28] OVRENPWRUPRXTXREF — Override enable of PwrupRxTxRef
    [27] OVRENFSSTART — Override enable of FsStart
    [26] OVRENARSTFS — Override enable of ArstFs
    [25] OVRENPWRUPFSDIV2G4COUNTER — Override enable of PwrupFsDiv2g4Counter
    [24] OVRENPWRUPFSDIV2 — Override enable of PwrupFsDiv2
    [23] OVRENPWRUPFSVCO — Override enable of PwrupFsVco
    [22] OVRENPWRUPFSTDC — Override enable of PwrupFsTdc
    [21] OVRENPWRUPFSDTC — Override enable of PwrupFsDtc
    [20:19] OVRENPWRUPFSLDOTDC — Override enable of PwrupFsLdoTdc
    [18:17] OVRENPWRUPFSLDOCNT — Override enable of PwrupFsLdoCnt
    [16:15] OVRENPWRUPFSLDODIV — Override enable of PwrupFsLdoDiv
    [14:13] OVRENPWRUPFSLDODIG — Override enable of PwrupFsLdoDig
    [12:11] OVRENPWRUPFSLDODTC — Override enable of PwrupFsLdoDtc
    [10:9] OVRENPWRUPFSLDOVCO — Override enable of PwrupFsLdoVco
    [8:6] OVRENRSTFSLS — Override enable of RstFsLs
    [5:3] OVRENPWRUPFSREF — Override enable of PwrupFsRef
    [2:1] OVRENPWRUPRADIO — Override enable of PwrupRadio
    [0] OVRENRETAINRADIO — Override enable of RetainRadio
  0x50 OVRENRXTX — Enable or disable override of signals
    [30] OVRENPWRUPRXLNAPDET — Override enable of PwrupRxLnaPdet
    [29] OVRENRXDIGEN — Override enable of rxDigEn
    [28] OVRENRXAGCEN — Override enable of rxAgcEn
    [27] OVRENSETRXIF — Override enable of setRxIf
    [26] OVRENPWRUPEXTPA — Override enable of PwrupExtPa
    [25] OVRENPWRUPEXTLNA — Override enable of PwrupExtLna
    [24] OVRENPWRUPTXPA — Override enable of PwrupTxPa
    [23] OVRENPWRUPTXPWRCTRL — Override enable of PwrupTxPwrCtrl
    [22] OVRENPWRUPTX — Override enable of PwrupTx
    [21:16] OVRENPWRUPTXLDO — Override enable of PwrupTxLdo
    [15] OVRENARSTADC — Override enable of ArstAdc
    [14] OVRENPWRUPRXPKD — Override enable of PwrupRxPkd
    [13:12] OVRENPWRUPRXSAR — Override enable of PwrupRxSar
    [11] OVRENPWRUPRXAAF — Override enable of PwrupRxAaf
    [10] OVRENPWRUPRX — Override enable of PwrupRx
    [9] OVRENPWRUPRXMIX — Override enable of PwrupRxMix
    [8] OVRENPWRUPRXLNA — Override enable of PwrupRxLna
    [7:2] OVRENPWRUPRXLDO — Override enable of PwrupRxLdo
    [1:0] OVRENRSTRXLS — Override enable of RstRxLs
  0x54 OVRVALALL — Set override values on signals
    [30:28] OVRVALPWRUPRXTXREF — Override value of PwrupRxTxRef
    [27] OVRVALFSSTART — Override value of FsStart
    [26] OVRVALARSTFS — Override value of ArstFs
    [25] OVRVALPWRUPFSDIV2G4COUNTER — Override value of PwrupFsDiv2g4Counter
    [24] OVRVALPWRUPFSDIV2 — Override value of PwrupFsDiv2
    [23] OVRVALPWRUPFSVCO — Override value of PwrupFsVco
    [22] OVRVALPWRUPFSTDC — Override value of PwrupFsTdc
    [21] OVRVALPWRUPFSDTC — Override value of PwrupFsDtc
    [20:19] OVRVALPWRUPFSLDOTDC — Override value of PwrupFsLdoTdc
    [18:17] OVRVALPWRUPFSLDOCNT — Override value of PwrupFsLdoCnt
    [16:15] OVRVALPWRUPFSLDODIV — Override value of PwrupFsLdoDiv
    [14:13] OVRVALPWRUPFSLDODIG — Override value of PwrupFsLdoDig
    [12:11] OVRVALPWRUPFSLDODTC — Override value of PwrupFsLdoDtc
    [10:9] OVRVALPWRUPFSLDOVCO — Override value of PwrupFsLdoVco
    [8:6] OVRVALRSTFSLS — Override value of RstFsLs
    [5:3] OVRVALPWRUPFSREF — Override value of PwrupFsRef
    [2:1] OVRVALPWRUPRADIO — Override value of PwrupRadio
    [0] OVRVALRETAINRADIO — Override value of RetainRadio
  0x58 OVRVALRXTX — Set override values on signals
    [30] OVRVALPWRUPRXLNAPDET — Override value of PwrupRxLnaPdet
    [29] OVRVALRXDIGEN — Override value of rxDigEn
    [28] OVRVALRXAGCEN — Override value of rxAgcEn
    [27] OVRVALSETRXIF — Override value of setRxIf
    [26] OVRVALPWRUPEXTPA — Override value of PwrupExtPa
    [25] OVRVALPWRUPEXTLNA — Override value of PwrupExtLna
    [24] OVRVALPWRUPTXPA — Override value of PwrupTxPa
    [23] OVRVALPWRUPTXPWRCTRL — Override value of PwrupTxPwrCtrl
    [22] OVRVALPWRUPTX — Override value of PwrupTx
    [21:16] OVRVALPWRUPTXLDO — Override value of PwrupTxLdo
    [15] OVRVALARSTADC — Override value of ArstAdc
    [14] OVRVALPWRUPRXPKD — Override value of PwrupRxPkd
    [13:12] OVRVALPWRUPRXSAR — Override value of PwrupRxSar
    [11] OVRVALPWRUPRXAAF — Override value of PwrupRxAaf
    [10] OVRVALPWRUPRX — Override value of PwrupRx
    [9] OVRVALPWRUPRXMIX — Override value of PwrupRxMix
    [8] OVRVALPWRUPRXLNA — Override value of PwrupRxLna
    [7:2] OVRVALPWRUPRXLDO — Override value of PwrupRxLdo
    [1:0] OVRVALRSTRXLS — Override value of RstRxLs
  0x5C MODEDEPENDENT2 reset 0x14 — Mode dependent timing controls
    [8] TURNOFFRADIOWRTTXDATAVALID — Turn off radio with regards to txDataValid in addition to radioEn
    [4:0] TTXRXTURNAROUNDDELTA — Additional offset in Rx mode, for Rx to be able to be ready earlier, which is required for 2Mbps
